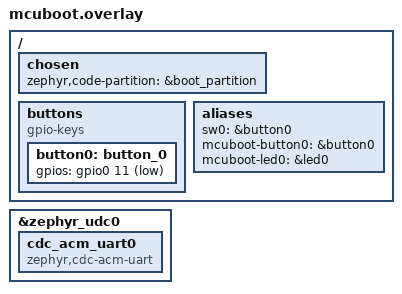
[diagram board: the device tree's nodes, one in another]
/*
 * MCUboot image overlay: serial-recovery CDC ACM + manual-recovery button
 * (from tikk-fleet tikk-pouch-demo — P0.11 button on the Tikk add-on).
 */

/* Shared flash layout (64 KB boot — the default 48 KB does not fit
 * this MCUboot config). Must match the app image's view of the map. */
#include "flash-layout.dtsi"

/ {
	chosen {
		/* The bootloader runs from boot_partition: the board dts
		 * points zephyr,code-partition at slot0 (right for the app
		 * image, wrong for MCUboot — without this override the
		 * bootloader links at slot0 and the board cannot boot). */
		zephyr,code-partition = &boot_partition;
	};
};

/ {
	buttons {
		compatible = "gpio-keys";

		button0: button_0 {
			gpios = <&gpio0 11 (GPIO_PULL_UP | GPIO_ACTIVE_LOW)>;
		};
	};

	aliases {
		sw0 = &button0;
		mcuboot-button0 = &button0;
		mcuboot-led0 = &led0;
	};
};

&zephyr_udc0 {
	cdc_acm_uart0: cdc_acm_uart0 {
		compatible = "zephyr,cdc-acm-uart";
	};
};
